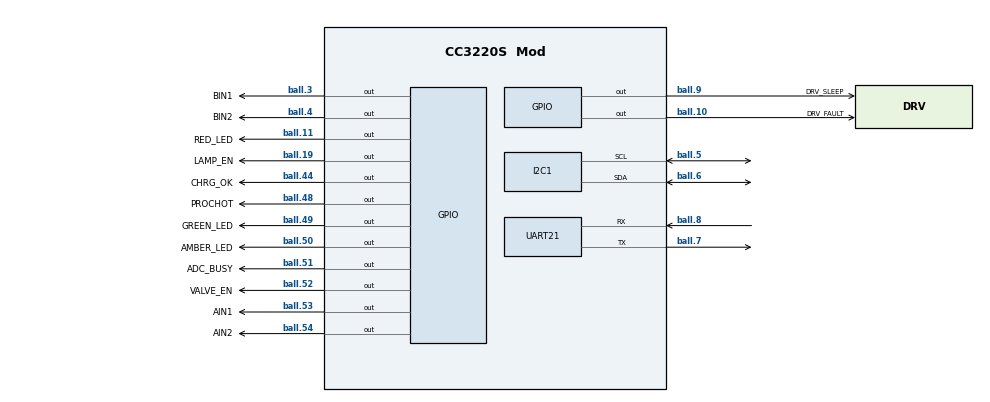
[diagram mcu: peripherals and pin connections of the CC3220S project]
/**
 * @cliArgs --device "CC3220S" --package "Mod" --part "Default" --rtos "tirtos7" --product "simplelink_cc32xx_sdk@6.10.00.05"
 * @versions {"tool":"1.15.0+2826"}
 */
scripting.excludeFromBuild("ti_utils_runtime_model.gv");
scripting.excludeFromBuild("ti_utils_runtime_Makefile");

/**
 * Import the modules used in this configuration.
 */
const GPIO           = scripting.addModule("/ti/drivers/GPIO", {}, false);
const GPIO1          = GPIO.addInstance();
const GPIO2          = GPIO.addInstance();
const GPIO3          = GPIO.addInstance();
const GPIO4          = GPIO.addInstance();
const GPIO5          = GPIO.addInstance();
const GPIO6          = GPIO.addInstance();
const GPIO7          = GPIO.addInstance();
const GPIO8          = GPIO.addInstance();
const GPIO9          = GPIO.addInstance();
const GPIO10         = GPIO.addInstance();
const GPIO11         = GPIO.addInstance();
const GPIO12         = GPIO.addInstance();
const GPIO13         = GPIO.addInstance();
const GPIO14         = GPIO.addInstance();
const I2C            = scripting.addModule("/ti/drivers/I2C", {}, false);
const I2C1           = I2C.addInstance();
const SPI            = scripting.addModule("/ti/drivers/SPI");
const UART2          = scripting.addModule("/ti/drivers/UART2", {}, false);
const UART21         = UART2.addInstance();
const SimpleLinkWifi = scripting.addModule("/ti/drivers/net/wifi/SimpleLinkWifi");
const SlNet          = scripting.addModule("/ti/net/SlNet", {}, false);
const SlNet1         = SlNet.addInstance();
const Settings       = scripting.addModule("/ti/posix/tirtos/Settings");
const BIOS           = scripting.addModule("/ti/sysbios/BIOS");

/**
 * Write custom configuration values to the imported modules.
 */
GPIO1.$name           = "AIN1";
GPIO1.mode            = "Output";
GPIO1.gpioPin.$assign = "ball.53";

GPIO2.$name           = "AIN2";
GPIO2.mode            = "Output";
GPIO2.gpioPin.$assign = "ball.54";

GPIO3.$name           = "DRV_SLEEP";
GPIO3.mode            = "Output";
GPIO3.gpioPin.$assign = "ball.9";

GPIO4.$name           = "DRV_FAULT";
GPIO4.gpioPin.$assign = "ball.10";

GPIO5.$name           = "GREEN_LED";
GPIO5.mode            = "Output";
GPIO5.gpioPin.$assign = "ball.49";

GPIO6.$name           = "AMBER_LED";
GPIO6.mode            = "Output";
GPIO6.gpioPin.$assign = "ball.50";

GPIO7.$name           = "RED_LED";
GPIO7.mode            = "Output";
GPIO7.gpioPin.$assign = "ball.11";

GPIO8.$name           = "CHRG_OK";
GPIO8.gpioPin.$assign = "ball.44";

GPIO9.$name           = "BIN1";
GPIO9.mode            = "Output";
GPIO9.gpioPin.$assign = "ball.3";

GPIO10.$name           = "BIN2";
GPIO10.mode            = "Output";
GPIO10.gpioPin.$assign = "ball.4";

GPIO11.$name           = "ADC_BUSY";
GPIO11.gpioPin.$assign = "ball.51";

GPIO12.$name           = "VALVE_EN";
GPIO12.mode            = "Output";
GPIO12.gpioPin.$assign = "ball.52";

GPIO13.$name           = "LAMP_EN";
GPIO13.mode            = "Output";
GPIO13.gpioPin.$assign = "ball.19";

GPIO14.$name           = "PROCHOT";
GPIO14.gpioPin.$assign = "ball.48";

I2C1.$name              = "MyI2C1";
I2C1.i2c.$assign        = "I2C0";
I2C1.i2c.sdaPin.$assign = "ball.6";
I2C1.i2c.sclPin.$assign = "ball.5";

const Power          = scripting.addModule("/ti/drivers/Power", {}, false);
Power.parkPins.$name = "ti_drivers_power_PowerCC32XXPins0";

UART21.$name              = "MyUART1";
UART21.uart.$assign       = "UART1";
UART21.uart.txPin.$assign = "ball.7";
UART21.uart.rxPin.$assign = "ball.8";

SimpleLinkWifi.connectionPolicy = ["(0,0,0,1)","(1,0,0,0)"];

SlNet1.$name = "MySlnet";

BIOS.heapSize     = 0x00002000;
BIOS.heapBaseAddr = "__primary_heap_start__";
BIOS.heapEndAddr  = "__primary_heap_end__";

/**
 * These are the reserved peripherals and settings in this configuration
 */
const iJTAG1       = scripting.addPeripheral("JTAG");
iJTAG1.$name       = "MyJTAG1";
iJTAG1.$assign     = "JTAG0";
iJTAG1.TDI.$assign = "ball.12";
iJTAG1.TDO.$assign = "ball.18";
iJTAG1.TCK.$assign = "ball.20";
iJTAG1.TMS.$assign = "ball.22";

/**
 * Pinmux solution for unlocked pins/peripherals. This ensures that minor changes to the automatic solver in a future
 * version of the tool will not impact the pinmux you originally saw.  These lines can be completely deleted in order to
 * re-solve from scratch.
 */
UART21.uart.txDmaChannel.$suggestSolution = "UDMA_CH11";
UART21.uart.rxDmaChannel.$suggestSolution = "UDMA_CH10";
